# ATtiny167 device description
Architecture: AVR8; Family: tinyAVR
Programming and debug interfaces: ISP, HVPP, debugWIRE
Registers are 8-bit, access not given, no defined reset value unless marked. A register's access mark holds for its fields unless they carry their own. Offsets are from the block's base; lines under a group give offsets from that group; [hi:lo] are bit positions; {n}, {i} and the like mark numbered series; 'fields as' and 'values as' point back to an identical list; <NAME> marks a mode.

## Ordering variants
ATtiny167-MU, ATtiny167-MUR: VQFN32, up to 16 MHz, -40 to 85 C, 1.8 to 5.5 V
ATtiny167-SU, ATtiny167-SUR: SOIC20, up to 16 MHz, -40 to 85 C, 1.8 to 5.5 V
ATtiny167-XU, ATtiny167-XUR: TSSOP20, up to 16 MHz, -40 to 85 C, 1.8 to 5.5 V

## Memory
prog space: start 0x0000 size 0x4000, little endian
  0x0000 FLASH size 0x4000 flash, rw, executable, page 0x80
signatures space: start 0 size 3, little endian
  0 SIGNATURES size 3 signatures, ro
fuses space: start 0 size 0x0003, little endian
  0 FUSES size 0x0003 fuses, rw
lockbits space: start 0 size 0x0001, little endian
  0 LOCKBITS size 0x0001 lockbits, rw
data space: start 0x0000 size 0x0300, little endian
  0x0000 REGISTERS size 0x0020 regs
  0x0020 MAPPED_IO size 0x00e0 io
  0x0100 IRAM size 0x0200 ram
eeprom space: start 0x0000 size 0x0200, little endian
  0x0000 EEPROM size 0x0200 eeprom, rw, page 0x04
io space: start 0x00 size 0x40, little endian
osccal space: start 0 size 1, little endian
  0 OSCCAL size 1 osccal, ro

## Peripheral instances (address, pins/pin function, parameters)
PORTA at 0x00 — I/O Port
PORTB at 0x00 — I/O Port
LINUART at 0x00 — Local Interconnect Network
USI at 0x00 — Universal Serial Interface
TC0 at 0x00 — Timer/Counter, 8-bit Async
TC1 at 0x00 — Timer/Counter, 16-bit
WDT at 0x00 — Watchdog Timer
EEPROM at 0x00
SPI at 0x00 — Serial Peripheral Interface
ADC at 0x00 — Analog-to-Digital Converter
CURRENT_SOURCE at 0x00
AC at 0x00 — Analog Comparator
EXINT at 0x00 — External Interrupts
BOOT_LOAD at 0x00 — Bootloader
CPU at 0x00 — CPU Registers
  parameters: CORE_VERSION=V2, NEW_INSTRUCTIONS=lpm rd,z+
FUSE at 0 in fuses — Fuses
LOCKBIT at 0 in lockbits — Lockbits

## Interrupts
0 RESET — External Reset, Power-on Reset and Watchdog Reset
1 INT0 — External Interrupt Request 0
2 INT1 — External Interrupt Request 1
3 PCINT0 — Pin Change Interrupt Request 0
4 PCINT1 — Pin Change Interrupt Request 1
5 WDT — Watchdog Time-Out Interrupt
6 TIMER1_CAPT — Timer/Counter1 Capture Event
7 TIMER1_COMPA — Timer/Counter1 Compare Match 1A
8 TIMER1_COMPB — Timer/Counter1 Compare Match 1B
9 TIMER1_OVF — Timer/Counter1 Overflow
10 TIMER0_COMPA — Timer/Counter0 Compare Match 0A
11 TIMER0_OVF — Timer/Counter0 Overflow
12 LIN_TC — LIN Transfer Complete
13 LIN_ERR — LIN Error
14 SPI_STC — SPI Serial Transfer Complete
15 ADC — ADC Conversion Complete
16 EE_RDY — EEPROM Ready
17 ANA_COMP — Analog Comparator
18 USI_START — USI Start Condition Detection
19 USI_OVF — USI Counter Overflow

## Properties
SIGNATURES: JTAGID=0x9487, SIGNATURE0=0x1e, SIGNATURE1=0x94, SIGNATURE2=0x87
OCD: OCD_REVISION=1, OCD_DATAREG=0x31, PROGBASE=0x0000

## LOCKBIT — Lockbits
Instances: LOCKBIT 0 in lockbits
0x00 LOCKBIT reset 0xFF
  [1:0] LB — Memory Lock
    0=PROG_VER_DISABLED (Further programming and verification disabled); 2=PROG_DISABLED (Further programming disabled); 3=NO_LOCK (No memory lock features enabled)

## PORTA — I/O Port
Instances: PORTA 0x00
0x20 PINA — Port A Input Pins
0x21 DDRA — Port A Data Direction Register
0x22 PORTA — Port A Data Register

## PORTB — I/O Port
Instances: PORTB 0x00
0x23 PINB — Port B Input Pins
0x24 DDRB — Port B Data Direction Register
0x25 PORTB — Port B Data Register

## LINUART — Local Interconnect Network
Instances: LINUART 0x00
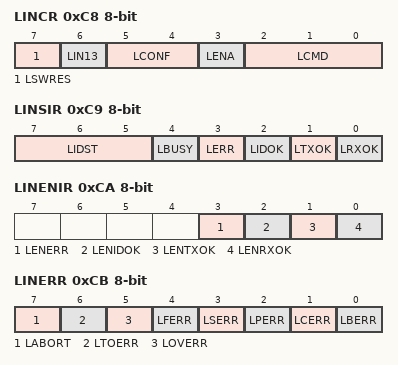
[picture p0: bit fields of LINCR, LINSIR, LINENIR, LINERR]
0xC8 LINCR — LIN Control Register
  [7] LSWRES — Software Reset
  [6] LIN13 — LIN Standard
  [5:4] LCONF — LIN Configuration bits
  [3] LENA — LIN or UART Enable
  [2:0] LCMD — LIN Command and Mode bits
0xC9 LINSIR — LIN Status and Interrupt Register
  [7:5] LIDST — Identifier Status bits
  [4] LBUSY — Busy Signal
  [3] LERR — Error Interrupt
  [2] LIDOK — Identifier Interrupt
  [1] LTXOK — Transmit Performed Interrupt
  [0] LRXOK — Receive Performed Interrupt
0xCA LINENIR — LIN Enable Interrupt Register
  [3] LENERR — Enable Error Interrupt
  [2] LENIDOK — Enable Identifier Interrupt
  [1] LENTXOK — Enable Transmit Performed Interrupt
  [0] LENRXOK — Enable Receive Performed Interrupt
0xCB LINERR — LIN Error Register
  [7] LABORT — Abort Flag
  [6] LTOERR — Frame Time Out Error Flag
  [5] LOVERR — Overrun Error Flag
  [4] LFERR — Framing Error Flag
  [3] LSERR — Synchronization Error Flag
  [2] LPERR — Parity Error Flag
  [1] LCERR — Checksum Error Flag
  [0] LBERR — Bit Error Flag
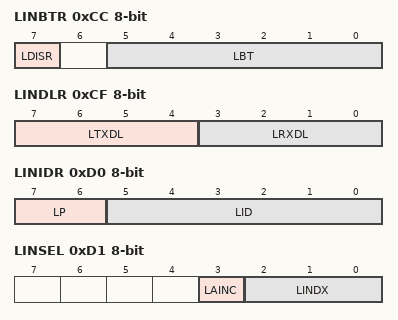
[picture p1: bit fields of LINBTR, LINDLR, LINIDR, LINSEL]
0xCC LINBTR — LIN Bit Timing Register
  [7] LDISR — Disable Bit Timing Resynchronization
  [5:0] LBT — LIN Bit Timing bits
0xCD LINBRRL — LIN Baud Rate Low Register
  [7:0] LDIV
0xCE LINBRRH — LIN Baud Rate High Register
  [3:0] LDIV (bit 8 of the value upward)
0xCF LINDLR — LIN Data Length Register
  [7:4] LTXDL — LIN Transmit Data Length bits
  [3:0] LRXDL — LIN Receive Data Length bits
0xD0 LINIDR — LIN Identifier Register
  [7:6] LP — Parity bits
  [5:0] LID — Identifier bit 5 or Data Length bits
0xD1 LINSEL — LIN Data Buffer Selection Register
  [3] LAINC — Auto Increment of Data Buffer Index (Active Low)
  [2:0] LINDX — FIFO LIN Data Buffer Index bits
0xD2 LINDAT — LIN Data Register
  [7:0] LDATA
